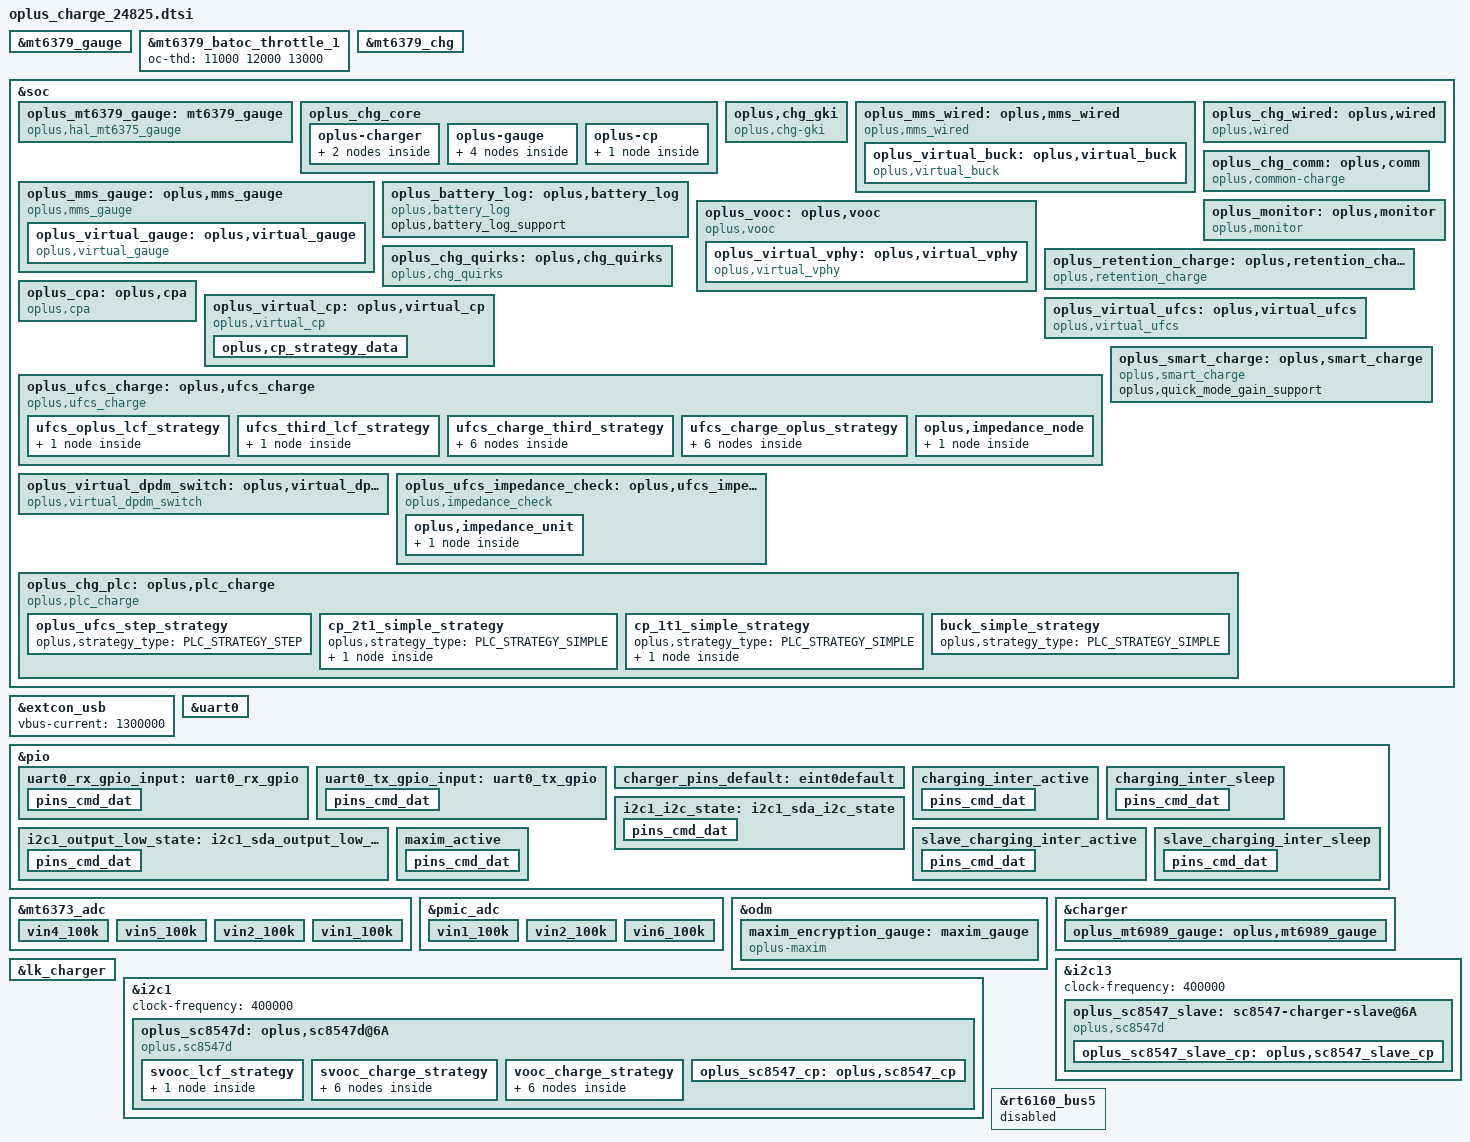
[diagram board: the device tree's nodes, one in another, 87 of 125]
// SPDX-License-Identifier: GPL-2.0-only
/*
* Copyright (C) 2024 Oplus. All rights reserved.
*/
#include <dt-bindings/iio/mt635x-auxadc.h>
#include <dt-bindings/iio/adc/mediatek,mt6379_auxadc.h>
#include <dt-bindings/pinctrl/mt6989-pinfunc.h>
#include <dt-bindings/pinctrl/mt65xx.h>
#include "oplus_chg.h"

/*
 *
 * CPU:MT6989V2 Subaru bcompare with MT6989V1 Nvwa, Platform Gauge Dtsi Config.
 *
 * UTXD0	-->GPIO203
 * URXD0	-->GPIO204
 *
 * I2C
 * MASTER_CHG	--> I2C5 MT6379 (GPIO99_SDA5, GPIO98_SCL5)
 * CP_MASTER	--> I2C1 SC8547D (GPIO101_SDA1, GPIO100_SCL1)
 * CP_SLAVE	--> I2C3 SC8547D (GPIO105_SDA3, GPIO104_SCL3)
 * Audio switch--> I2C6 Audio switch (GPIO226_SDA5, GPIO225_SCL5)
 *
 * IRQB
 * EINT_CHG_1 (cp1 irq)			--> GPIO83
 * EINT_CHG_2 (cp2 irq)			--> GPIO200
 * MT6375Z irq				--> GPIO175
 *
 * GPIO
 * VBUS_SHORT(防烧口)			--> MT6373 MOS_CON1
 * SEC_IC (加密电池GPIO for 80W)	--> GPIO190
 * 区分平台电量计和外置电量计GPIO	--> GPIO208 (低是石墨，高是硅负, 默认高电平)
 *
 *
 * ADC:
 * MT6363-GPIO1				--> VBAT_TEMP_ADC (电池仓温度检测NTC)(小板ntc温度)
 * MT6379 BATON				--> BATON_TH (电池保护板温度)
 * MT6363-GPIO6				--> USBCON_TEM_ADC_MCU (usb btb)
 *
 * MT6373 AUXADC_VIN4			--> USB_TEMP_ADC1 防烧口NTC1
 * MT6373 AUXADC_VIN5			--> USB_TEMP_ADC1 防烧口NTC2
 * MT6363 AUXADC_VIN1			--> CP_MOS_THERM 充电温度检测ntc   CP_TEM_ADC  靠近快充CP2和副电池BTB放置(3-6mm)
 * MT6363-GPIO2				--> BATCON_TEM_ADC_MCU (battery btb)
 *
 */

/* charge start */
&mt6379_gauge {
	status = "okay";
	charger = <&mt6379_chg>;
	FUELGAGUE_APPLY = <(1)>;
	IS_SUBBOARD_TEMP_SUPPORT = <(0)>;
	EXTERNAL_AUTHENTICATE =<(1)>;
	Enable_Is_Force_Full = <(1)>;

	active-table = <(5)>;
	r-fg-value = <(1)>;/* R_sense resistance. evb1 use 2; evb2 and later use 1 milliohm */
	com-r-fg-value = <(-1)>;/* R_sense compensate resistance. use COM_R_FG_VALUE */
	UNIT_MULTIPLE = <(1)>;
	RBAT_PULL_DOWN_R = <(24000)>;
	RBAT_PULL_UP_R = <(12000)>;
	RBAT_PULL_UP_VOLT = <(1840)>; /* Need to upadted  based on the PCB design.*/
	USE_MORE_PRECISE_NTC_TABLE = <(1)>;
	car-tune-value = <(99)>;      /* Current Calibration, need to upadted  based on the PCB design.*/
	DIM2_TABLE_DISTINGUISH = <(1)>;
	keep-100-percent-minsoc = <(9500)>;
	aging-factor-diff = <(1)>;
	keep-100-percent = <(2)>;

	/* compensate The resistance of PCB */
	com-fg-meter-resistance = <(-17)>;

	/* The resistance of PCB */
	fg-meter-resistance = <(-17)>;
	#include "bat_setting/mt6989_battery_prop_dim2_ext_24825.dtsi"
	#include "bat_setting/mt6989_battery_table_24825.dtsi"
};

&mt6379_batoc_throttle_1 {
	/* update the batoc-thd to avoid the issue of bat_oc interrup when the master BTB not connected */
	oc-thd = <11000 12000 13000>;
};

&mt6379_chg {
	chg-tmr = <15>;
	ircmp_v = <0>;
};

&soc {
	oplus_mt6379_gauge: mt6379_gauge {
		status = "okay";
		compatible = "oplus,hal_mt6375_gauge";

		oplus,ic_type = <OPLUS_CHG_IC_GAUGE>;
		oplus,ic_index = <0>;
		oplus,batt_num = <1>;
		oplus,mtk_gauge_power_sel_support;
		oplus,mtk_gauge_cali_track_support;
		oplus,mtk_gauge_power_sel_by_power_support;

		/* subaru graphite sub btb valid temperature range, which is provided by hardware engineer. */
		oplus,sub_btb_valid_temp = <(-350) 1000>;
	};
};

&extcon_usb {
	vbus-current = <1300000>;
};

&uart0 {
	pinctrl-names = "uart0_rx_gpio", "uart0_tx_gpio";
	pinctrl-0 = <&uart0_rx_gpio_input>;
	pinctrl-1 = <&uart0_tx_gpio_input>;
	status = "okay";

	txpin = <203>;
	rxpin = <204>;
};

&pio {
	uart0_rx_gpio_input: uart0_rx_gpio {
		pins_cmd_dat {
			pinmux = <PINMUX_GPIO204__FUNC_GPIO204>;
			input-enable;
			bias-disable;
		};
	};

	uart0_tx_gpio_input: uart0_tx_gpio {
		pins_cmd_dat {
			pinmux = <PINMUX_GPIO203__FUNC_GPIO203>;
			input-enable;
			bias-disable;
		};
	};
};

/* mt6373_adc is defined in mt6373.dtsi */
&mt6373_adc {
	vin4_100k {
		channel = <AUXADC_VIN4>;
		pures = <ADC_PURES_100K>;
	};
	vin5_100k {
		channel = <AUXADC_VIN5>;
		pures = <ADC_PURES_100K>;
	};
	vin2_100k {
		channel = <AUXADC_VIN2>;
		pures = <ADC_PURES_100K>;
	};
	vin1_100k {
		channel = <AUXADC_VIN1>;
		pures = <ADC_PURES_100K>;
	};
};

/* pmic_adc is defined in mt6363.dtsi */
&pmic_adc {
	vin1_100k {
		channel = <AUXADC_VIN1>;
		pures = <ADC_PURES_100K>;
	};
	vin2_100k {
		channel = <AUXADC_VIN2>;
		pures = <ADC_PURES_100K>;
	};
	vin6_100k {
		channel = <AUXADC_VIN6>;
		pures = <ADC_PURES_100K>;
	};
};

&pio {
	charger_pins_default: eint0default {
	};

	charging_inter_active: charging_inter_active {
		pins_cmd_dat {
			pinmux = <PINMUX_GPIO83__FUNC_GPIO83>;
			input-enable;
			bias-pull-up;
		};
	};

	charging_inter_sleep: charging_inter_sleep {
		pins_cmd_dat {
			pinmux = <PINMUX_GPIO83__FUNC_GPIO83>;
			input-enable;
			bias-pull-up;
		};
	};

	i2c1_i2c_state: i2c1_sda_i2c_state {
		pins_cmd_dat {
			pinmux = <PINMUX_GPIO100__FUNC_SCL1>,
				 <PINMUX_GPIO101__FUNC_SDA1>;
			bias-disable;
		};
	};

	i2c1_output_low_state: i2c1_sda_output_low_state {
		pins_cmd_dat {
			pinmux = <PINMUX_GPIO100__FUNC_GPIO100>,
				 <PINMUX_GPIO101__FUNC_GPIO101>;
			output-low;
		};
	};

	slave_charging_inter_active: slave_charging_inter_active {
		pins_cmd_dat {
			pinmux = <PINMUX_GPIO200__FUNC_GPIO200>;
			input-enable;
			bias-pull-up;
		};
	};

	slave_charging_inter_sleep: slave_charging_inter_sleep {
		pins_cmd_dat {
			pinmux = <PINMUX_GPIO200__FUNC_GPIO200>;
			input-enable;
			bias-pull-up;
		};
	};
};

&soc {
	oplus_chg_core {
		oplus,chg_framework_v2;
		oplus,battery_type_by_cmdline;
		oplus,smart_charging_screenoff;
		oplus,chg_spec_version = <OPLUS_CHG_SPEC_VER_V3P7>;

		oplus-charger {
			mtk_6989_groups: oplus,mtk_6989_groups {
				functions = <
					OPLUS_IC_FUNC_INIT
					OPLUS_IC_FUNC_EXIT
					OPLUS_IC_FUNC_REG_DUMP
					OPLUS_IC_FUNC_SMT_TEST
					OPLUS_IC_FUNC_BUCK_INPUT_PRESENT
					OPLUS_IC_FUNC_BUCK_INPUT_SUSPEND
					OPLUS_IC_FUNC_BUCK_INPUT_IS_SUSPEND
					OPLUS_IC_FUNC_BUCK_OUTPUT_SUSPEND
					OPLUS_IC_FUNC_BUCK_OUTPUT_IS_SUSPEND
					OPLUS_IC_FUNC_BUCK_SET_ICL
					OPLUS_IC_FUNC_BUCK_GET_ICL
					OPLUS_IC_FUNC_BUCK_SET_FCC
					OPLUS_IC_FUNC_BUCK_SET_FV
					OPLUS_IC_FUNC_BUCK_SET_ITERM
					OPLUS_IC_FUNC_BUCK_GET_INPUT_CURR
					OPLUS_IC_FUNC_BUCK_GET_INPUT_VOL
					OPLUS_IC_FUNC_OTG_BOOST_ENABLE
					OPLUS_IC_FUNC_BUCK_GET_CC_ORIENTATION
					OPLUS_IC_FUNC_BUCK_GET_CHARGER_TYPE
					OPLUS_IC_FUNC_BUCK_RERUN_BC12
					OPLUS_IC_FUNC_BUCK_QC_DETECT_ENABLE
					OPLUS_IC_FUNC_BUCK_SET_QC_CONFIG
					OPLUS_IC_FUNC_BUCK_SET_PD_CONFIG
					OPLUS_IC_FUNC_GET_SHUTDOWN_SOC
					OPLUS_IC_FUNC_BACKUP_SOC
					OPLUS_IC_FUNC_GET_TYPEC_MODE
					OPLUS_IC_FUNC_SET_TYPEC_MODE
					OPLUS_IC_FUNC_GET_TYPEC_ROLE
					OPLUS_IC_FUNC_GET_OTG_ENABLE
					OPLUS_IC_FUNC_BUCK_GET_HW_DETECT
					OPLUS_IC_FUNC_SET_USB_DISCHG_ENABLE
					OPLUS_IC_FUNC_GET_USB_DISCHG_STATUS
					OPLUS_IC_FUNC_IS_OPLUS_SVID
					OPLUS_IC_FUNC_BUCK_GET_USB_BTB_TEMP
					OPLUS_IC_FUNC_BUCK_GET_BATT_BTB_TEMP
					OPLUS_IC_FUNC_BUCK_SHIPMODE_ENABLE
					OPLUS_IC_FUNC_BUCK_SET_AICL_POINT
					OPLUS_IC_FUNC_SET_OTG_BOOST_CURR_LIMIT
					OPLUS_IC_FUNC_SET_OTG_BOOST_VOL
					OPLUS_IC_FUNC_BUCK_GET_FV
					OPLUS_IC_FUNC_BUCK_GET_TYPEC_STATE
					OPLUS_IC_FUNC_BUCK_GET_USB_AICL_ENHANCE
				>;
				virqs = <
					OPLUS_IC_VIRQ_ERR
					OPLUS_IC_VIRQ_CC_DETECT
					OPLUS_IC_VIRQ_PLUGIN
					OPLUS_IC_VIRQ_CC_CHANGED
					OPLUS_IC_VIRQ_CHG_TYPE_CHANGE
					OPLUS_IC_VIRQ_OTG_ENABLE
					OPLUS_IC_VIRQ_SVID
					OPLUS_IC_VIRQ_TYPEC_STATE
					OPLUS_IC_VIRQ_PD_COMPLETED
				>;
			};

			byb_tps6128xd_groups: oplus,byb-tps6128xd-groups {
				functions = <
					OPLUS_IC_FUNC_INIT
					OPLUS_IC_FUNC_EXIT
					OPLUS_IC_FUNC_REG_DUMP
				>;
				virqs = <
					OPLUS_IC_VIRQ_ERR
				>;
			};
		};

		oplus-gauge {
			mt6379_gauge_groups: oplus,mt6379_gauge_groups {
				functions = <
					OPLUS_IC_FUNC_INIT
					OPLUS_IC_FUNC_EXIT
					OPLUS_IC_FUNC_REG_DUMP
					OPLUS_IC_FUNC_SMT_TEST
					OPLUS_IC_FUNC_GAUGE_GET_BATT_VOL
					OPLUS_IC_FUNC_GAUGE_GET_BATT_MAX
					OPLUS_IC_FUNC_GAUGE_GET_BATT_MIN
					OPLUS_IC_FUNC_GAUGE_GET_BATT_CURR
					OPLUS_IC_FUNC_GAUGE_GET_BATT_TEMP
					OPLUS_IC_FUNC_GAUGE_GET_BATT_SOC
					OPLUS_IC_FUNC_GAUGE_GET_BATT_FCC
					OPLUS_IC_FUNC_GAUGE_GET_BATT_CC
					OPLUS_IC_FUNC_GAUGE_GET_BATT_RM
					OPLUS_IC_FUNC_GAUGE_GET_BATT_SOH
					OPLUS_IC_FUNC_GAUGE_GET_BATT_HMAC
					OPLUS_IC_FUNC_GAUGE_SET_BATT_FULL
					OPLUS_IC_FUNC_GAUGE_UPDATE_DOD0
					OPLUS_IC_FUNC_GAUGE_UPDATE_SOC_SMOOTH
					OPLUS_IC_FUNC_GAUGE_GET_CB_STATUS
					OPLUS_IC_FUNC_GAUGE_GET_BATT_NUM
					OPLUS_IC_FUNC_GAUGE_GET_DEVICE_TYPE
					OPLUS_IC_FUNC_GAUGE_GET_DEVICE_TYPE_FOR_VOOC
					OPLUS_IC_FUNC_GAUGE_GET_BATT_FCC
					OPLUS_IC_FUNC_GAUGE_GET_BATT_FC
					OPLUS_IC_FUNC_GAUGE_GET_BATT_QM
					OPLUS_IC_FUNC_GAUGE_GET_BATT_PD
					OPLUS_IC_FUNC_GAUGE_GET_BATT_RCU
					OPLUS_IC_FUNC_GAUGE_GET_BATT_RCF
					OPLUS_IC_FUNC_GAUGE_GET_BATT_FCU
					OPLUS_IC_FUNC_GAUGE_GET_BATT_FCF
					OPLUS_IC_FUNC_GAUGE_GET_BATT_SOU
					OPLUS_IC_FUNC_GAUGE_GET_BATT_DO0
					OPLUS_IC_FUNC_GAUGE_GET_BATT_DOE
					OPLUS_IC_FUNC_GAUGE_GET_BATT_TRM
					OPLUS_IC_FUNC_GAUGE_GET_BATT_PC
					OPLUS_IC_FUNC_GAUGE_GET_BATT_QS
					OPLUS_IC_FUNC_GAUGE_IS_SUSPEND
					OPLUS_IC_FUNC_GAUGE_GET_BCC_PARMS
					OPLUS_IC_FUNC_GAUGE_FASTCHG_UPDATE_BCC_PARMS
					OPLUS_IC_FUNC_GAUGE_GET_PREV_BCC_PARMS
					OPLUS_IC_FUNC_GAUGE_SET_BCC_PARMS
					OPLUS_IC_FUNC_GAUGE_SET_PROTECT_CHECK
					OPLUS_IC_FUNC_GAUGE_GET_AFI_UPDATE_DONE
					OPLUS_IC_FUNC_GAUGE_CHECK_RESET
					OPLUS_IC_FUNC_GAUGE_GET_DEVICE_TYPE_FOR_BCC
					OPLUS_IC_FUNC_GAUGE_GET_DOD0
					OPLUS_IC_FUNC_GAUGE_GET_DOD0_PASSED_Q
					OPLUS_IC_FUNC_GAUGE_GET_QMAX
					OPLUS_IC_FUNC_GAUGE_GET_QMAX_PASSED_Q
					OPLUS_IC_FUNC_GAUGE_SET_BATTERY_CURVE
					OPLUS_IC_FUNC_GAUGE_GET_GAUGE_CAR_C
					OPLUS_IC_FUNC_GAUGE_GET_SUB_BTB_CONNECT_STATE
					OPLUS_IC_FUNC_GAUGE_GET_DEC_FG_TYPE
					OPLUS_IC_FUNC_GAUGE_GET_DEC_CV_SOH
					OPLUS_IC_FUNC_GAUGE_SET_VCT
					OPLUS_IC_FUNC_GAUGE_GET_VCT
				>;
				virqs = <
					OPLUS_IC_VIRQ_ERR
					OPLUS_IC_VIRQ_OFFLINE
					OPLUS_IC_VIRQ_RESUME
				>;
			};

			mt6989_gauge_groups: oplus,mt6989_gauge_groups {
				functions = <
					OPLUS_IC_FUNC_INIT
					OPLUS_IC_FUNC_EXIT
					OPLUS_IC_FUNC_GAUGE_GET_SUBBOARD_TEMP
				>;
				virqs = <
					OPLUS_IC_VIRQ_ERR
				>;
			};

			maxim_encryption_gauge_groups: oplus,maxim_encryption_gauge_groups {
				functions = <
					OPLUS_IC_FUNC_INIT
					OPLUS_IC_FUNC_EXIT
					OPLUS_IC_FUNC_GAUGE_GET_BATT_AUTH
				>;
				virqs = <
					OPLUS_IC_VIRQ_ERR
				>;
			};

			bq27541_groups: oplus,bq27541_groups {
				functions = <
					OPLUS_IC_FUNC_INIT
					OPLUS_IC_FUNC_EXIT
					OPLUS_IC_FUNC_REG_DUMP
					OPLUS_IC_FUNC_SMT_TEST
					OPLUS_IC_FUNC_GAUGE_GET_BATT_VOL
					OPLUS_IC_FUNC_GAUGE_GET_BATT_MAX
					OPLUS_IC_FUNC_GAUGE_GET_BATT_MIN
					OPLUS_IC_FUNC_GAUGE_GET_BATT_CURR
					OPLUS_IC_FUNC_GAUGE_GET_BATT_TEMP
					OPLUS_IC_FUNC_GAUGE_GET_BATT_SOC
					OPLUS_IC_FUNC_GAUGE_GET_BATT_FCC
					OPLUS_IC_FUNC_GAUGE_GET_BATT_CC
					OPLUS_IC_FUNC_GAUGE_GET_BATT_RM
					OPLUS_IC_FUNC_GAUGE_GET_BATT_SOH
					OPLUS_IC_FUNC_GAUGE_GET_BATT_AUTH
					OPLUS_IC_FUNC_GAUGE_GET_BATT_HMAC
					OPLUS_IC_FUNC_GAUGE_SET_BATT_FULL
					OPLUS_IC_FUNC_GAUGE_UPDATE_DOD0
					OPLUS_IC_FUNC_GAUGE_UPDATE_SOC_SMOOTH
					OPLUS_IC_FUNC_GAUGE_GET_CB_STATUS
					OPLUS_IC_FUNC_GAUGE_GET_BATT_NUM
					OPLUS_IC_FUNC_GAUGE_GET_DEVICE_TYPE
					OPLUS_IC_FUNC_GAUGE_GET_DEVICE_TYPE_FOR_VOOC
					OPLUS_IC_FUNC_GAUGE_GET_BATT_FCC
					OPLUS_IC_FUNC_GAUGE_GET_BATT_FC
					OPLUS_IC_FUNC_GAUGE_GET_BATT_QM
					OPLUS_IC_FUNC_GAUGE_GET_BATT_PD
					OPLUS_IC_FUNC_GAUGE_GET_BATT_RCU
					OPLUS_IC_FUNC_GAUGE_GET_BATT_RCF
					OPLUS_IC_FUNC_GAUGE_GET_BATT_FCU
					OPLUS_IC_FUNC_GAUGE_GET_BATT_FCF
					OPLUS_IC_FUNC_GAUGE_GET_BATT_SOU
					OPLUS_IC_FUNC_GAUGE_GET_BATT_DO0
					OPLUS_IC_FUNC_GAUGE_GET_BATT_DOE
					OPLUS_IC_FUNC_GAUGE_GET_BATT_TRM
					OPLUS_IC_FUNC_GAUGE_GET_BATT_PC
					OPLUS_IC_FUNC_GAUGE_GET_BATT_QS
					OPLUS_IC_FUNC_GAUGE_IS_SUSPEND
					OPLUS_IC_FUNC_GAUGE_GET_BCC_PARMS
					OPLUS_IC_FUNC_GAUGE_FASTCHG_UPDATE_BCC_PARMS
					OPLUS_IC_FUNC_GAUGE_GET_PREV_BCC_PARMS
					OPLUS_IC_FUNC_GAUGE_SET_BCC_PARMS
					OPLUS_IC_FUNC_GAUGE_SET_PROTECT_CHECK
					OPLUS_IC_FUNC_GAUGE_GET_AFI_UPDATE_DONE
					OPLUS_IC_FUNC_GAUGE_CHECK_RESET
					OPLUS_IC_FUNC_GAUGE_SET_RESET
					OPLUS_IC_FUNC_GAUGE_GET_DEVICE_TYPE_FOR_BCC
					OPLUS_IC_FUNC_GAUGE_GET_DOD0
					OPLUS_IC_FUNC_GAUGE_GET_DOD0_PASSED_Q
					OPLUS_IC_FUNC_GAUGE_GET_QMAX
					OPLUS_IC_FUNC_GAUGE_GET_QMAX_PASSED_Q
					OPLUS_IC_FUNC_GAUGE_GET_REG_INFO
					OPLUS_IC_FUNC_GAUGE_GET_CALIB_TIME
					OPLUS_IC_FUNC_GAUGE_GET_DEEP_DISCHG_COUNT
					OPLUS_IC_FUNC_GAUGE_SET_DEEP_DISCHG_COUNT
					OPLUS_IC_FUNC_GAUGE_GET_DEEP_TERM_VOLT
					OPLUS_IC_FUNC_GAUGE_SET_DEEP_TERM_VOLT
					OPLUS_IC_FUNC_GAUGE_SET_SILI_SPARE_POWER
					OPLUS_IC_FUNC_GAUGE_GET_SILI_SIMULATE_TERM_VOLT
					OPLUS_IC_FUNC_GAUGE_GET_SILI_IC_ALG_TERM_VOLT
					OPLUS_IC_FUNC_GAUGE_SET_SILI_IC_ALG_CFG
					OPLUS_IC_FUNC_GAUGE_GET_SILI_IC_ALG_DSG_ENABLE
					OPLUS_IC_FUNC_GAUGE_SET_SILI_IC_ALG_TERM_VOLT
					OPLUS_IC_FUNC_GAUGE_GET_SILI_ALG_APPLICATION_INFO
					OPLUS_IC_FUNC_GAUGE_GET_SILI_LIFETIME_STATUS
					OPLUS_IC_FUNC_GAUGE_GET_SILI_LIFETIME_INFO
					OPLUS_IC_FUNC_GAUGE_SET_CALIB_TIME
					OPLUS_IC_FUNC_GAUGE_SET_LAST_CC
					OPLUS_IC_FUNC_GAUGE_GET_LAST_CC
				>;
				virqs = <
					OPLUS_IC_VIRQ_ERR
					OPLUS_IC_VIRQ_OFFLINE
					OPLUS_IC_VIRQ_RESUME
				>;
			};
		};

		oplus-cp {
			sc8547_cp_groups: oplus,cp_groups {
				functions = <
					OPLUS_IC_FUNC_INIT
					OPLUS_IC_FUNC_EXIT
					OPLUS_IC_FUNC_REG_DUMP
					OPLUS_IC_FUNC_SMT_TEST
					OPLUS_IC_FUNC_CP_ENABLE
					OPLUS_IC_FUNC_CP_HW_INTI
					OPLUS_IC_FUNC_CP_SET_WORK_START
					OPLUS_IC_FUNC_CP_CHECK_WORK_MODE_SUPPORT
					OPLUS_IC_FUNC_CP_SET_WORK_MODE
					OPLUS_IC_FUNC_CP_GET_WORK_MODE
					OPLUS_IC_FUNC_CP_GET_VIN
					OPLUS_IC_FUNC_CP_GET_IIN
					OPLUS_IC_FUNC_CP_SET_IIN
					OPLUS_IC_FUNC_CP_GET_VOUT
					OPLUS_IC_FUNC_CP_GET_IOUT
					OPLUS_IC_FUNC_CP_GET_VAC
					OPLUS_IC_FUNC_CP_GET_WORK_STATUS
					OPLUS_IC_FUNC_CP_SET_ADC_ENABLE
					OPLUS_IC_FUNC_CP_WATCHDOG_ENABLE
					OPLUS_IC_FUNC_CP_SET_UCP_DISABLE
					OPLUS_IC_FUNC_CP_GET_IIN_MAX
					OPLUS_IC_FUNC_CP_WATCHDOG_RESET
				>;
				virqs = <
					OPLUS_IC_VIRQ_ERR
					OPLUS_IC_VIRQ_ONLINE
					OPLUS_IC_VIRQ_OFFLINE
				>;
			};
		};
	};
};


&pio {
	maxim_active: maxim_active {
		pins_cmd_dat {
			pinmux = <PINMUX_GPIO190__FUNC_GPIO190>;
				//slew-rate = <1>;
				drive-strength = <6>;
				bias-pull-up;
			};
		};
};

&odm {
	maxim_encryption_gauge: maxim_gauge {
		status = "okay";
		compatible = "oplus-maxim";
		pinctrl-names = "maxim_active";
		pinctrl-0 = <&maxim_active>;
		support_encryption_in_lk;
		data-gpio = <&pio 190 0x00>;

		gpio-addr-set-out = <0x10005004>;
		gpio-addr-set-in = <0x10005008>;
		gpio-addr-level_high = <0x10005104>;
		gpio-addr-level_low = <0x10005108>;
		gpio-addr-data-in = <0x10005200>;
		gpio-addr-offset = <0xbe>;

		/* TODO: need to update when the battery material code updated */
		oplus,batt_info = /bits/ 8 <0x36 0x31 0x31 0x33 0x30 0x33 0x30 0x30 0x30 0x31 0x33 0x31
					    0x36 0x31 0x31 0x33 0x30 0x33 0x30 0x30 0x30 0x32 0x32 0x38>;

		oplus,ic_type = <OPLUS_CHG_IC_GAUGE>;
		oplus,ic_index = <2>;
	};
};

&soc {
	oplus,chg_gki {
		compatible = "oplus,chg-gki";
	};
};

&charger {
	io-channels = <&pmic_adc (ADC_PURES_100K_MASK | AUXADC_VIN2)>,
			<&mt6373_adc AUXADC_VIN1>,
			<&pmic_adc (ADC_PURES_100K_MASK | AUXADC_VIN1)>,
			<&pmic_adc (ADC_PURES_100K_MASK | AUXADC_VIN2)>,
			<&pmic_adc (ADC_PURES_100K_MASK | AUXADC_VIN6)>,
			<&mt6373_adc AUXADC_VIN1>;
	io-channel-names = "master_cp_temp","slave_cp_temp", "auxadc1-ntc_sub_bat_tem",
			   "auxadc5_batt_btb_temp", "auxadc6_usb_btb_temp", "sub_bat_btb_temp";

	pinctrl-names = "default";
	pinctrl-0 = <&charger_pins_default>;
	oplus,support_ntc_01c_precision;
	oplus,support_subboard_ntc;
	max_charger_voltage = <15000000>;

	/* ntc_resistance:100k internal_pull_up:100k voltage:1.84v */
	oplus,ntc_temp_volt_1840mv;

	/* usbtemp dischg use pmic regulator to set vbus down */
	oplus,support_usbtemp_dischg_reg_configurable;
	oplus,usbtemp_dischg_reg_addr = <0x989>;
	oplus,usbtemp_dischg_reg_mask = <0x7>;
	oplus,usbtemp_dischg_enable = <0x2>;
	oplus,usbtemp_dischg_disable = <0x0>;
	oplus,ic_type = <OPLUS_CHG_IC_BUCK>;
	oplus,ic_index = <0>;

	oplus,usb_aicl_enhance;

	oplus_mt6989_gauge: oplus,mt6989_gauge {
		oplus,ic_type = <OPLUS_CHG_IC_GAUGE>;
		oplus,ic_index = <1>;
	};
};

&lk_charger {
	is_support_mt6379;
	en_vol_ctrl_vibrate = <3200>;
	support_tuv_authentication;
	high-temp-scheme;
	charger_no_wiress;
	support_battery_type = <8>;
	support_maxim_battery_authentication;
	data-gpio = <190>;

	/* TODO: need to update when the battery material code updated */
	oplus,batt_info = /bits/ 8 <0x36 0x31 0x31 0x33 0x30 0x33 0x30 0x30 0x30 0x31 0x33 0x31
				    0x36 0x31 0x31 0x33 0x30 0x33 0x30 0x30 0x30 0x32 0x32 0x38>;

	oplus,batt_resource_info = /bits/ 8 <1 0>;
	sub_board_temp_support;
	over_high_temp_thr = <60>;
	sub_board_adc_channel = <18>; /* AUXADC_VIN1 */
	sub_board_adc_pull_up_voltage = <1840>;

	support_sdp_screenoff;
	sdp_screenon_voltage = <3250>;
	support_quickboot_charge;

	/* mt6989 start */
	led-brightness = <102>;

	/* mt6989, such as max_charger_voltage to max-charger-voltage */
	max-charger-voltage = <15000000>;
	boot-battery-voltage = <3350000>;
	usb-charger-current = <500000>;
	ac-charger-current = <2050000>;
	ac-charger-input-current = <1500000>;
	non-std-ac-charger-current = <750000>;
	charging-host-charger-current = <1500000>;
	ta-ac-charger-current = <1500000>;
	pd-charger-current = <500000>;

	/* support to read the vbat by the 6379 gauge. */
	mt6379_gauge_support;

	/* support to get the gauge type by the board gpio. */
	gauge_type_by_gpio = <208>;

	/* 1: silicon, 0: graphite. */
	gauge_silicon_gpio_value = <1>;
	/* mt6989 end */
};

&soc {
	oplus_mms_wired: oplus,mms_wired {
		compatible = "oplus,mms_wired";
		oplus,buck_ic = <&oplus_virtual_buck>;
		oplus,voocphy_ic = <&oplus_virtual_vphy>;

		oplus,adc_info_name = "100k_1840mv";
		oplus_spec,usbtemp_batttemp_gap = <12>;
		high-temp-scheme;

		/* support for V2.0 usbtemp protect. */
		oplus,support_usbtemp_protect_v2;
		oplus_spec,usbtemp_batt_temp_low = <50>;
		oplus_spec,usbtemp_batt_temp_high = <50>;
		oplus_spec,usbtemp_batt_temp_over_hot = <60>;
		oplus_spec,usbtemp_ntc_temp_low = <57>;
		oplus_spec,usbtemp_ntc_temp_high = <69>;
		oplus_spec,usbtemp_temp_gap_low_with_batt_temp = <7>;
		oplus_spec,usbtemp_temp_gap_with_batt_temp_in_over_hot = <15>;
		oplus_spec,usbtemp_temp_gap_high_with_batt_temp = <12>;
		oplus_spec,usbtemp_temp_gap_low_without_batt_temp = <12>;
		oplus_spec,usbtemp_temp_gap_high_without_batt_temp = <24>;
		oplus_spec,usbtemp_rise_fast_temp_low = <3>;
		oplus_spec,usbtemp_rise_fast_temp_high = <3>;
		oplus_spec,usbtemp_rise_fast_temp_count_low = <30>;
		oplus_spec,usbtemp_rise_fast_temp_count_high = <20>;
		oplus_spec,usbtemp_cool_down_ntc_low = <54>;
		oplus_spec,usbtemp_cool_down_ntc_high = <65>;
		oplus_spec,usbtemp_cool_down_gap_low = <12>;
		oplus_spec,usbtemp_cool_down_gap_high = <20>;
		oplus_spec,usbtemp_cool_down_recover_ntc_low = <48>;
		oplus_spec,usbtemp_cool_down_recover_ntc_high = <60>;
		oplus_spec,usbtemp_cool_down_recover_gap_low = <6>;
		oplus_spec,usbtemp_cool_down_recover_gap_high = <15>;
		oplus_spec,usbtemp_otg_cc_boot_current_limit = <1300000>;

		oplus_virtual_buck: oplus,virtual_buck {
			compatible = "oplus,virtual_buck";
			oplus,buck_ic = <&charger>;
			oplus,buck_ic_index = <0>;
			oplus,buck_ic_current_ratio = <100>;
			oplus,buck_ic_connect = <OPLUS_CHG_IC_CONNECT_PARALLEL>;
			oplus,main_charger = <0>;

			oplus,buck_ic_func_group = <&mtk_6989_groups>;

			oplus,ic_type = <OPLUS_CHG_IC_VIRTUAL_BUCK>;
			oplus,ic_index = <0>;

			io-channels = <&mt6373_adc AUXADC_VIN4>, <&mt6373_adc AUXADC_VIN5>;
			io-channel-names = "usb_temp_adc_l", "usb_temp_adc_r";

			oplus,uart_tx-gpio = <&pio 203 0x00>;
			oplus,uart_rx-gpio = <&pio 204 0x00>;
		};
	};

	oplus_mms_gauge: oplus,mms_gauge {
		compatible = "oplus,mms_gauge";
		oplus,gauge_ic = <&oplus_virtual_gauge>;
		oplus,voocphy_ic = <&oplus_virtual_vphy>;
		oplus,topic-update-interval = <10000>;
		oplus,support_subboard_ntc;
		oplus,sub_btb_curr_limit = <3000>; /* Online current limiting, provided by hardware engineer */

		oplus_virtual_gauge: oplus,virtual_gauge {
			compatible = "oplus,virtual_gauge";
			oplus,gauge_ic =  <&oplus_mt6379_gauge &oplus_mt6989_gauge &maxim_encryption_gauge>;
			plus,gauge_ic_index = <0 1 2>;
			oplus,gauge_ic_func_group = <&mt6379_gauge_groups &mt6989_gauge_groups &maxim_encryption_gauge_groups>;
			oplus,batt_capacity_mah = <7100>;
			oplus,ic_type = <OPLUS_CHG_IC_VIRTUAL_GAUGE>;
			oplus,ic_index = <0>;
		};
	};
};

&soc {
	oplus_battery_log: oplus,battery_log {
		compatible = "oplus,battery_log";
		oplus,battery_log_support;
	};

	oplus_chg_wired: oplus,wired {
		compatible = "oplus,wired";

		oplus,vooc-support;
		oplus_spec,vbatt_pdqc_to_5v_thr = <4500>;
		oplus_spec,vbatt_pdqc_to_9v_thr = <4500>;
		oplus_spec,pd-iclmax-ma = <2000>;
		oplus_spec,qc-iclmax-ma = <2000>;
		oplus_spec,non-standard-ibatmax-ma = <500>;
		oplus_spec,input-power-mw = <
			2500		/* OPLUS_WIRED_CHG_MODE_UNKNOWN */
			2500		/* OPLUS_WIRED_CHG_MODE_SDP */
			7500		/* OPLUS_WIRED_CHG_MODE_CDP */
			10000		/* OPLUS_WIRED_CHG_MODE_DCP */
			18000		/* OPLUS_WIRED_CHG_MODE_VOOC */
			18000		/* OPLUS_WIRED_CHG_MODE_QC */
			18000		/* OPLUS_WIRED_CHG_MODE_PD */
		>;
		oplus_spec,led_on-fccmax-ma = <0 1732 4400 4400 4400 4400 4400 1000 0>;
		oplus_spec,fccmax-ma-lv = <
			0 1363 2200 2200 2200 2200 2200 2200 0	/* OPLUS_WIRED_CHG_MODE_UNKNOWN */
			0 600  600  600  600  600  600  600  0	/* OPLUS_WIRED_CHG_MODE_SDP */
			0 1600 1600 1600 1600 1600 1600 1600 0	/* OPLUS_WIRED_CHG_MODE_CDP */
			0 1732 2200 2200 2200 2200 2200 2200 0	/* OPLUS_WIRED_CHG_MODE_DCP */
			0 1732 4400 4400 4400 4400 4400 3811 0	/* OPLUS_WIRED_CHG_MODE_VOOC */
			0 1732 4400 4400 4400 4400 4400 3811 0	/* OPLUS_WIRED_CHG_MODE_QC */
			0 1732 4400 4400 4400 4400 4400 3811 0	/* OPLUS_WIRED_CHG_MODE_PD */
		>;
		oplus_spec,fccmax-ma-hv = <
			0 1363 2200 2200 2200 2200 2200 1000 0	/* OPLUS_WIRED_CHG_MODE_UNKNOWN */
			0 600  600  600  600  600  600  500 0	/* OPLUS_WIRED_CHG_MODE_SDP */
			0 1600 1600 1600 1600 1600 1600 1000 0	/* OPLUS_WIRED_CHG_MODE_CDP */
			0 1732 2200 2200 2200 2200 2200 1000 0	/* OPLUS_WIRED_CHG_MODE_DCP */
			0 1732 4400 4400 4400 4400 4400 1000 0	/* OPLUS_WIRED_CHG_MODE_VOOC */
			0 1732 4400 4400 4400 4400 4400 1000 0	/* OPLUS_WIRED_CHG_MODE_QC */
			0 1732 4400 4400 4400 4400 4400 1000 0	/* OPLUS_WIRED_CHG_MODE_PD */
		>;
		oplus_spec,cool_down_sale_pdqc_vol_mv = <5000>;
		oplus_spec,cool_down_sale_pdqc_curr_ma = <1200>;
		oplus_spec,cool_down_pdqc_vol_mv = <5000 5000 5000 9000 9000>;
		oplus_spec,cool_down_pdqc_curr_ma = <1200 1500 2000 1500 2000>;
		oplus_spec,cool_down_vooc_curr_ma = <1200 1500 2000 2500 3000 3000>;
		oplus_spec,cool_down_normal_curr_ma = <1200 1500 2000>;

		oplus_spec,vbus_ov_thr_mv = <11000 11000>;
		oplus_spec,vbus_uv_thr_mv = <4300 4300>;

		/* Temperature control for power off charging. */
		/* first data is strategy used temp type */
		oplus,pd_strategy_name = "cgcl";
		oplus,pd_strategy_data = <OPLUS_STRATEGY_USE_SHELL_TEMP
					    0   420 2000 1 0
					    410 430 1500 2 0
					    420 440 1200 2 1>;

		oplus,qc_strategy_name = "cgcl";
		oplus,qc_strategy_data = <OPLUS_STRATEGY_USE_SHELL_TEMP
					    0   420 2000 1 0
					    410 430 1500 2 0
					    420 440 1200 2 1>;
	};

	oplus_chg_comm: oplus,comm {
		compatible = "oplus,common-charge";
		oplus_spec,dec_step = <20>;
		oplus_spec,dec-vol-cc-full-thr = <0 400 600 800 1000 1200>;
		oplus_spec,dec-vol-fv-full-mv = <0 20 20 40 40 40>;
		oplus_spec,batt-them-thr = <(-100) 0 50 120 160 350 450 530>;
		oplus_spec,iterm-ma = <365>; /* 7100*0.05+10 */
		oplus_spec,removed_bat_decidegc = <390>; /*-39 degree*/
		oplus_spec,fv-mv = <4490 4490 4490 4490 4490 4490 4470 4130 4130>;
		oplus_spec,sw-fv-mv = <4440 4440 4440 4440 4440 4440 4420 4080 4080>;
		oplus_spec,hw-fv-inc-mv = <0 18 18 18 18 18 18 18 0>;
		oplus_spec,sw-over-fv-mv = <4500 4500 4500 4500 4500 4500 4480 4140 4140>;
		oplus_spec,sw-over-fv-dec-mv = <8>;
		oplus_spec,non-standard-sw-fv-mv = <3930>;
		oplus_spec,non-standard-fv-mv = <3980>;
		oplus_spec,non-standard-hw-fv-inc-mv = <18>;
		oplus_spec,non-standard-sw-over-fv-mv = <3990>;
		oplus_spec,non-standard-vbatdet-mv = <3680>;
		oplus_spec,wired-vbatdet-mv = <0 4190 4290 4390 4390 4390 4370 4030 0>;
		oplus_spec,fcc-gear-thr-mv = <4180>;
		oplus_spec,fcc-gear-shake-mv = <700 700 400 250 200 150 150 100 100>;
		oplus_spec,vbatt-ov-thr-mv = <4600>;

		oplus_spec,full_pre_ffc_judge;
		oplus_spec,full-pre-ffc-mv = <4500>;
		oplus_spec,ffc-temp-thr = <120 210 350 440>;
		oplus_spec,wired-ffc-step-max = <2>;
		oplus_spec,wired-ffc-fv-mv = <4630 4630>;

		oplus_spec,wired-ffc-fv-cutoff-mv = <4565 4550 4520
						     4565 4535 4495>;
		oplus_spec,wired-ffc-fcc-ma = <1750 1500 1500
					       1650 1000 1000>;
		oplus_spec,wired-ffc-fcc-cutoff-ma = <1550 1300 1300
						      1550 900 900>;
		oplus_spec,vbat_uv_thr_mv = <3300>;
		oplus_spec,vbat_charging_uv_thr_mv = <3200>;

		oplus_spec,tbatt_power_off_cali_temp = <0>;
		oplus_spec,poweroff_high_batt_temp = <720>;
		oplus_spec,poweroff_emergency_batt_temp = <770>;
		oplus,vooc_show_ui_soc_decimal;
		oplus,ui_soc_decimal_speedmin = <20>;
		oplus,gauge_stuck_jump_support;
		oplus,gauge_stuck_threshold = <15>;
		oplus,gauge_stuck_time = <50>;

		oplus_spec,batt_full_time = <300>;
	};

	oplus_monitor: oplus,monitor {
		compatible = "oplus,monitor";
		oplus,topic-update-interval = <60000>;

		track,fast_chg_break_t_thd = <1400>;
		track,general_chg_break_t_thd = <300>;
		track,voocphy_type = <TRACK_AP_DUAL_CP_VOOCPHY>;
		track,wired_max_power = <80000>;
		track,wired_fast_chg_scheme = <2>;
	};

	oplus_vooc: oplus,vooc {
		compatible = "oplus,vooc";
		oplus,vooc_ic = <&oplus_virtual_vphy>;

		oplus_spec,vooc_soc_range = <50 75 85>;

		oplus,vooc_data_width = <7>;
		oplus,vooc_curr_max = <CP_CURR_LIMIT_7BIT_15_0A>; /* 80W: 11V 7.3A(IBUS *2) */
		oplus,vooc_power_max_w = <80>;
		oplus,vooc_project = <7>;
		oplus,vooc_curr_table_type = <VOOC_CP_CURR_TABLE>;
		oplus,voocphy_support = <3>; /* AP_DUAL_CP_VOOCPHY */
		oplus,support_fake_vooc_check;
		oplus,subboard_ntc_abnormal_current = <4000>;
		oplus,cp_cooldown_limit_percent_75 = <CP_CURR_LIMIT_7BIT_8_0A>;
		oplus,cp_cooldown_limit_percent_85 = <CP_CURR_LIMIT_7BIT_4_0A>;

		oplus,abnormal_adapter_current = <CP_CURR_LIMIT_7BIT_15_0A CP_CURR_LIMIT_7BIT_15_0A
						CP_CURR_LIMIT_7BIT_10_0A CP_CURR_LIMIT_7BIT_10_0A
						CP_CURR_LIMIT_7BIT_8_0A CP_CURR_LIMIT_7BIT_8_0A
						CP_CURR_LIMIT_7BIT_6_0A CP_CURR_LIMIT_7BIT_6_0A
						CP_CURR_LIMIT_7BIT_4_0A CP_CURR_LIMIT_7BIT_4_0A>;

		oplus,abnormal_over_80w_adapter_current = <CP_CURR_LIMIT_7BIT_15_0A CP_CURR_LIMIT_7BIT_15_0A
						CP_CURR_LIMIT_7BIT_14_0A CP_CURR_LIMIT_7BIT_14_0A
						CP_CURR_LIMIT_7BIT_12_0A CP_CURR_LIMIT_7BIT_12_0A
						CP_CURR_LIMIT_7BIT_10_0A CP_CURR_LIMIT_7BIT_10_0A
						CP_CURR_LIMIT_7BIT_8_0A CP_CURR_LIMIT_7BIT_8_0A
						CP_CURR_LIMIT_7BIT_6_0A CP_CURR_LIMIT_7BIT_6_0A
						CP_CURR_LIMIT_7BIT_4_0A CP_CURR_LIMIT_7BIT_4_0A>;

		/* Temperature control for power off charging */
		/* first data is strategy used temp type */
		oplus,general_strategy_name = "cgcl";
		oplus,general_strategy_data = < OPLUS_STRATEGY_USE_SHELL_TEMP
						0   385 CP_CURR_LIMIT_7BIT_15_0A 1 0
						375 405 CP_CURR_LIMIT_7BIT_10_0A 2 0
						395 420 CP_CURR_LIMIT_7BIT_8_0A 3 1
						410 430 CP_CURR_LIMIT_7BIT_7_0A 4 2
						425 440 CP_CURR_LIMIT_7BIT_4_0A 4 3 >;

		oplus,bypass_strategy_name = "cgcl";
		oplus,bypass_strategy_data = <OPLUS_STRATEGY_USE_SHELL_TEMP
						0   350 CP_CURR_LIMIT_7BIT_6_0A 1 0
						340 380 CP_CURR_LIMIT_7BIT_5_0A 2 0
						370 440 CP_CURR_LIMIT_7BIT_4_0A 2 1>;

		oplus,plc_strategy-data = <&buck_simple_strategy &cp_2t1_simple_strategy &cp_1t1_simple_strategy>;
		oplus,plc_strategy-names = "default", "svooc", "vooc";

		oplus_virtual_vphy: oplus,virtual_vphy {
			compatible = "oplus,virtual_vphy";
			oplus,vphy_ic = <&oplus_sc8547d>;

			oplus,ic_type = <OPLUS_CHG_IC_VIRTUAL_VPHY>;
			oplus,ic_index = <0>;
			oplus,dpdm_switch_ic = <&oplus_virtual_dpdm_switch>;
		};
	};

	oplus_chg_quirks: oplus,chg_quirks {
		compatible = "oplus,chg_quirks";
	};
	oplus_retention_charge: oplus,retention_charge {
		compatible = "oplus,retention_charge";
		oplus,topic-update-interval = <5000>;
		oplus,support_retention_name = "oplus_retention_quirks";
	};

	oplus_cpa: oplus,cpa {
		compatible = "oplus,cpa";
		oplus,protocol_list = <CHG_PROTOCOL_UFCS 80
				       CHG_PROTOCOL_VOOC 80
				       CHG_PROTOCOL_PD 18
				       CHG_PROTOCOL_QC 18>;
		oplus,default_protocol_list = <CHG_PROTOCOL_UFCS
					       CHG_PROTOCOL_VOOC
					       CHG_PROTOCOL_PD>;

		oplus,protocol_wait_list = <CHG_PROTOCOL_UFCS 1000>;
	};

	oplus_virtual_cp: oplus,virtual_cp {
		compatible = "oplus,virtual_cp";

		oplus,ic_type = <OPLUS_CHG_IC_VIRTUAL_CP>;
		oplus,ic_index = <0>;

		oplus,cp_ic = <&oplus_sc8547_cp &oplus_sc8547_slave_cp>;
		oplus,input_curr_max_ma = <4000 4000>;

		oplus,cp_ic_connect = <OPLUS_CHG_IC_CONNECT_PARALLEL>;
		oplus,main_cp = <0>;

		oplus,reg_proc_node;

		oplus,cp_strategy = <CP_STRAT_OPEN_BY_CURR>;
		oplus,cp_strategy_data {
			oplus,cp_open_curr_thr_ma = <0 1900>;
			oplus,cp_close_curr_thr_ma = <0 1600>;
		};
	};

	oplus_virtual_ufcs: oplus,virtual_ufcs {
		compatible = "oplus,virtual_ufcs";

		oplus,ic_type = <OPLUS_CHG_IC_VIRTUAL_UFCS>;
		oplus,ic_index = <0>;
	};

	oplus_ufcs_charge: oplus,ufcs_charge {
		compatible = "oplus,ufcs_charge";
		oplus,ufcs_ic = <&oplus_virtual_ufcs>;
		oplus,cp_ic = <&oplus_virtual_cp>;
		oplus,dpdm_switch_ic = <&oplus_virtual_dpdm_switch>;

		oplus,impedance_unit = <&oplus_ufcs_impedance_unit>;
		oplus,ufcs_need_reset_adapter;

		oplus,target_vbus_mv = <11000>;
		oplus,curr_max_ma = <7300>;
		oplus,curr_table_type = <UFCS_CURR_CP_TABLE>;
		oplus,high_imp_compensation_setting_mv = <250>;
		oplus,upper_compensation_mv = <200>;
		oplus,lift_vbus_use_cpvout;
		oplus,subboard_ntc_abnormal_current = <4000>;

		oplus,ufcs_warm_allow_vol = <4000>;
		oplus,ufcs_warm_allow_soc = <50>;
		oplus,ufcs_strategy_normal_current = <7300>;
		oplus,ufcs_over_high_or_low_current = <7300>;
		oplus,ufcs_timeout_third = <17820>;
		oplus,ufcs_timeout_oplus = <17820>;
		oplus,ufcs_ibat_over_third = <9400>;
		oplus,ufcs_ibat_over_oplus = <16000>;
		oplus,ufcs_full_cool_sw_vbat = <4570>;
		oplus,ufcs_full_normal_sw_vbat = <4570>;
		oplus,ufcs_full_normal_hw_vbat = <4580>;
		oplus,ufcs_full_ffc_vbat = <4520>;
		oplus,ufcs_full_warm_vbat = <4130>;
		oplus,ufcs_full_cool_sw_vbat_third = <4500>;
		oplus,ufcs_full_normal_sw_vbat_third= <4510>;
		oplus,ufcs_full_normal_hw_vbat_third = <4520>;
		oplus,ufcs_current_change_timeout = <100>;
		oplus,ufcs_strategy_batt_high_temp = <405 420 430 395 410 425>;
		oplus,ufcs_strategy_high_current = <5000 4000 3000 5000 4000 3000>;
		oplus,ufcs_little_cool_high_temp = <210>;
		oplus,curve_strategy_name = "pps_ufcs_curve_v2";
		oplus_spec,ufcs_high_soc = <90>;
		oplus_spec,ufcs_high_soc_third = <85>;
		oplus,ufcs_charge_strategy_soc = <0 20 35 50 75 85 90>;
		oplus,ufcs_charge_strategy_temp = <0 50 120 160 350 440 510>;

		oplus,plc_strategy-data = <&oplus_ufcs_step_strategy &cp_2t1_simple_strategy>;
		oplus,plc_strategy-names = "default", "third";

		/* Temperature control for power off charging */
		oplus,temperature_strategy_name = "cgcl";
		oplus,temperature_strategy_data = <OPLUS_STRATEGY_USE_SHELL_TEMP
						0   385 7300 1 0
						375 405 5000 2 0
						395 420 4000 3 1
						410 430 3500 4 2
						420 440 2000 4 3>;

		ufcs_oplus_lcf_strategy {
			oplus,temp_type = <OPLUS_STRATEGY_USE_SHELL_TEMP>;
			oplus,temp_range = <0 50 120 160 210 380 440>;

			strategy_temp_range_curves {
				strategy_temp_range_t0 =	<800 4570 0
								 750 4560 0
								 700 4550 0
								 650 4540 0
								 600 4530 1>;
				strategy_temp_range_t1 =	<950 4570 0
								 900 4565 0
								 850 4550 0
								 750 4540 0
								 650 4530 1>;
				strategy_temp_range_t2 =	<1050 4570 0
								 1000 4565 0
								 900 4550 0
								 800 4540 0
								 650 4530 1>;
				strategy_temp_range_t3 =	<1600 4570 0
								 1550 4565 0
								 1450 4550 0
								 1350 4540 0
								 1200 4530 1>;
				strategy_temp_range_t4 =	<2150 4570 0
								 2100 4565 0
								 2000 4550 0
								 1900 4540 0
								 1750 4530 1>;
				strategy_temp_range_t5 =	<2900 4565 0
								 2450 4550 0
								 2000 4530 0
								 1500 4510 0
								 1000 4495 1>;
			};
		};

		ufcs_third_lcf_strategy {
			oplus,temp_type = <OPLUS_STRATEGY_USE_SHELL_TEMP>;
			oplus,temp_range = <0 50 120 160 210 380 440>;

			strategy_temp_range_curves {
				strategy_temp_range_t0 =	<800 4570 0
								 750 4560 0
								 700 4550 0
								 650 4540 0
								 600 4530 1>;
				strategy_temp_range_t1 =	<950 4570 0
								 900 4565 0
								 850 4550 0
								 750 4540 0
								 650 4530 1>;
				strategy_temp_range_t2 =	<1050 4570 0
								 1000 4565 0
								 900 4550 0
								 800 4540 0
								 650 4530 1>;
				strategy_temp_range_t3 =	<1600 4570 0
								 1550 4565 0
								 1450 4550 0
								 1350 4540 0
								 1200 4530 1>;
				strategy_temp_range_t4 =	<2150 4570 0
								 2100 4565 0
								 2000 4550 0
								 1900 4540 0
								 1750 4530 1>;
				strategy_temp_range_t5 =	<2900 4565 0
								 2450 4550 0
								 2000 4530 0
								 1500 4510 0
								 1000 4495 1>;
			};
		};

		ufcs_charge_third_strategy {
			oplus,temp_type = <OPLUS_STRATEGY_USE_SHELL_TEMP>;
			oplus,soc_range = <0 20 35 55 75 85 90>;
			oplus,temp_range = <0 50 120 160 210 350 440 510>;

			strategy_soc_range_min {
				strategy_temp_little_cold =	<11000 4150 3950 0 0
								11000 4150 3500 0 0
								11000 4150 3000 0 0
								11000 4480 2650 0 0
								11000 4480 2500 0 0
								11000 4480 2000 0 0
								11000 4480 1950 0 0
								11000 4480 1500 0 0
								11000 4490 1000 1 0>;
				strategy_temp_cool =		<11000 4150 4000 0 0
								11000 4480 3950 0 0
								11000 4480 3500 0 0
								11000 4480 3000 0 0
								11000 4480 2650 0 0
								11000 4480 2500 0 0
								11000 4480 2000 0 0
								11000 4480 1500 0 0
								11000 4490 1000 1 0>;
				strategy_temp_little_cool =	<11000 4480 4000 0 0
								11000 4480 3500 0 0
								11000 4480 3000 0 0
								11000 4480 2500 0 0
								11000 4480 2000 0 0
								11000 4480 1500 0 0
								11000 4490 1000 1 0>;
				strategy_temp_little_cool_high =	<11000 4480 4000 0 0
								11000 4480 3500 0 0
								11000 4480 3000 0 0
								11000 4480 2500 0 0
								11000 4480 2000 0 0
								11000 4480 1500 0 0
								11000 4490 1000 1 0>;
				strategy_temp_normal_low =	<11000 4480 4000 0 0
								11000 4480 3500 0 0
								11000 4480 3000 0 0
								11000 4480 2500 0 0
								11000 4480 2000 0 0
								11000 4480 1500 0 0
								11000 4490 1000 1 0>;
				strategy_temp_normal_high =	<11000 4460 4000 0 0
								11000 4460 3500 0 0
								11000 4460 3000 0 0
								11000 4460 2500 0 0
								11000 4460 2000 0 0
								11000 4460 1500 0 0
								11000 4470 1000 1 0>;
				strategy_temp_warm =		<11000 4120 1900 0 0
								11000 4120 1500 0 0
								11000 4130 1000 1 0>;
			};
			strategy_soc_range_low {
				strategy_temp_little_cold =	<11000 4150 3950 0 0
								11000 4150 3500 0 0
								11000 4150 3000 0 0
								11000 4480 2650 0 0
								11000 4480 2500 0 0
								11000 4480 2000 0 0
								11000 4480 1950 0 0
								11000 4480 1500 0 0
								11000 4490 1000 1 0>;
				strategy_temp_cool =		<11000 4150 4000 0 0
								11000 4480 3950 0 0
								11000 4480 3500 0 0
								11000 4480 3000 0 0
								11000 4480 2650 0 0
								11000 4480 2500 0 0
								11000 4480 2000 0 0
								11000 4480 1500 0 0
								11000 4490 1000 1 0>;
				strategy_temp_little_cool =	<11000 4480 4000 0 0
								11000 4480 3500 0 0
								11000 4480 3000 0 0
								11000 4480 2500 0 0
								11000 4480 2000 0 0
								11000 4480 1500 0 0
								11000 4490 1000 1 0>;
				strategy_temp_little_cool_high =	<11000 4480 4000 0 0
								11000 4480 3500 0 0
								11000 4480 3000 0 0
								11000 4480 2500 0 0
								11000 4480 2000 0 0
								11000 4480 1500 0 0
								11000 4490 1000 1 0>;
				strategy_temp_normal_low =	<11000 4480 4000 0 0
								11000 4480 3500 0 0
								11000 4480 3000 0 0
								11000 4480 2500 0 0
								11000 4480 2000 0 0
								11000 4480 1500 0 0
								11000 4490 1000 1 0>;
				strategy_temp_normal_high =	<11000 4460 4000 0 0
								11000 4460 3500 0 0
								11000 4460 3000 0 0
								11000 4460 2500 0 0
								11000 4460 2000 0 0
								11000 4460 1500 0 0
								11000 4470 1000 1 0>;
				strategy_temp_warm =		<11000 4120 1900 0 0
								11000 4120 1500 0 0
								11000 4130 1000 1 0>;
			};
			strategy_soc_range_mid_low {
				strategy_temp_little_cold =	<11000 4480 2000 0 0
								11000 4480 1950 0 0
								11000 4480 1500 0 0
								11000 4490 1000 1 0>;
				strategy_temp_cool =		<11000 4480 2500 0 0
								11000 4480 2000 0 0
								11000 4480 1500 0 0
								11000 4490 1000 1 0>;
				strategy_temp_little_cool =	<11000 4480 3000 0 0
								11000 4480 2500 0 0
								11000 4480 2000 0 0
								11000 4480 1500 0 0
								11000 4490 1000 1 0>;
				strategy_temp_little_cool_high =	<11000 4480 3000 0 0
								11000 4480 2500 0 0
								11000 4480 2000 0 0
								11000 4480 1500 0 0
								11000 4490 1000 1 0>;
				strategy_temp_normal_low =	<11000 4480 4000 0 0
								11000 4480 3500 0 0
								11000 4480 3000 0 0
								11000 4480 2500 0 0
								11000 4480 2000 0 0
								11000 4480 1500 0 0
								11000 4490 1000 1 0>;
				strategy_temp_normal_high =	<11000 4460 4000 0 0
								11000 4460 3500 0 0
								11000 4460 3000 0 0
								11000 4460 2500 0 0
								11000 4460 2000 0 0
								11000 4460 1500 0 0
								11000 4470 1000 1 0>;
				strategy_temp_warm =		<11000 4120 1900 0 0
								11000 4120 1500 0 0
								11000 4130 1000 1 0>;
			};
			strategy_soc_range_mid {
				strategy_temp_little_cold =	<11000 4480 1500 0 0
								11000 4490 1000 1 0>;
				strategy_temp_cool =		<11000 4480 1500 0 0
								11000 4490 1000 1 0>;
				strategy_temp_little_cool =	<11000 4480 2000 0 0
								11000 4480 1500 0 0
								11000 4490 1000 1 0>;
				strategy_temp_little_cool_high =	<11000 4480 2000 0 0
								11000 4480 1500 0 0
								11000 4490 1000 1 0>;
				strategy_temp_normal_low =	<11000 4480 2000 0 0
								11000 4480 1500 0 0
								11000 4490 1000 1 0>;
				strategy_temp_normal_high =	<11000 4460 2500 0 0
								11000 4460 2000 0 0
								11000 4460 1500 0 0
								11000 4470 1000 1 0>;
				strategy_temp_warm =		<11000 4130 1100 1 0>;
			};
			strategy_soc_range_mid_high {
				strategy_temp_little_cold =	<11000 4490 1000 1 0>;
				strategy_temp_cool =		<11000 4490 1000 1 0>;
				strategy_temp_little_cool =	<11000 4490 1000 1 0>;
				strategy_temp_little_cool_high =	<11000 4490 1000 1 0>;
				strategy_temp_normal_low =	<11000 4480 1500 0 0
								11000 4490 1000 1 0>;
				strategy_temp_normal_high =	<11000 4460 1500 0 0
								11000 4470 1000 1 0>;
				strategy_temp_warm =		<11000 4130 1100 1 0>;
			};
			strategy_soc_range_high {
				strategy_temp_little_cold =	<11000 4490 1100 1 0>;
				strategy_temp_cool =		<11000 4490 1100 1 0>;
				strategy_temp_little_cool =	<11000 4490 1100 1 0>;
				strategy_temp_little_cool_high =	<11000 4490 1100 1 0>;
				strategy_temp_normal_low =	<11000 4490 1100 1 0>;
				strategy_temp_normal_high =	<11000 4470 1100 1 0>;
				strategy_temp_warm =		<11000 4130 1100 1 0>;
			};
		};

		ufcs_charge_oplus_strategy {
			oplus,temp_type = <OPLUS_STRATEGY_USE_SHELL_TEMP>;
			oplus,soc_range = <0 20 35 55 75 85 90>;
			oplus,temp_range = <0 50 120 160 210 350 440 510>;

			strategy_soc_range_min {
				strategy_temp_little_cold =	<11000 4150 3950 0 0
								11000 4150 3500 0 0
								11000 4150 3000 0 0
								11000 4510 2650 0 0
								11000 4510 2500 0 0
								11000 4510 2000 0 0
								11000 4560 1950 0 0
								11000 4560 1500 0 0
								11000 4570 1000 1 0>;
				strategy_temp_cool =		<11000 4150 4950 0 0
								11000 4150 4500 0 0
								11000 4150 4000 0 0
								11000 4510 3950 0 0
								11000 4510 3500 0 0
								11000 4510 3000 0 0
								11000 4560 2650 0 0
								11000 4560 2500 0 0
								11000 4560 2000 0 0
								11000 4560 1500 0 0
								11000 4570 1000 1 0>;
				strategy_temp_little_cool =	<11000 4150 7300 0 60
								11000 4150 6100 0 180
								11000 4510 5950 0 240
								11000 4510 5000 0 180
								11000 4560 4650 0 240
								11000 4560 4000 0 300
								11000 4560 3500 0 0
								11000 4560 3000 0 0
								11000 4560 2500 0 0
								11000 4560 2000 0 0
								11000 4560 1500 0 0
								11000 4570 1000 1 0>;
				strategy_temp_little_cool_high =	<11000 4280 7300 0 30
								11000 4510 6300 0 30
								11000 4510 5000 0 240
								11000 4560 4650 0 300
								11000 4560 4000 0 600
								11000 4560 3500 0 0
								11000 4560 3000 0 0
								11000 4560 2500 0 0
								11000 4560 2000 0 0
								11000 4560 1500 0 0
								11000 4570 1000 1 0>;
				strategy_temp_normal_low =	<11000 4280 7300 0 30
								11000 4510 6300 0 30
								11000 4510 5000 0 240
								11000 4560 4650 0 300
								11000 4560 4000 0 600
								11000 4560 3500 0 0
								11000 4560 3000 0 0
								11000 4560 2500 0 0
								11000 4560 2000 0 0
								11000 4560 1500 0 0
								11000 4570 1100 1 0>;
				strategy_temp_normal_high =	<11000 4280 7300 0 30
								11000 4510 6300 0 30
								11000 4510 5000 0 240
								11000 4560 4650 0 300
								11000 4560 4000 0 900
								11000 4560 3500 0 0
								11000 4560 3000 0 0
								11000 4560 2500 0 0
								11000 4560 2000 0 0
								11000 4570 1500 0 0
								11000 4530 1000 1 0>;
				strategy_temp_warm =		<11000 4120 1900 0 0
								11000 4120 1500 0 0
								11000 4130 1000 1 0>;
			};
			strategy_soc_range_low {
				strategy_temp_little_cold =	<11000 4150 3950 0 0
								11000 4150 3500 0 0
								11000 4150 3000 0 0
								11000 4510 2650 0 0
								11000 4510 2500 0 0
								11000 4510 2000 0 0
								11000 4560 1950 0 0
								11000 4560 1500 0 0
								11000 4570 1000 1 0>;
				strategy_temp_cool =		<11000 4150 4950 0 0
								11000 4150 4500 0 0
								11000 4150 4000 0 0
								11000 4510 3950 0 0
								11000 4510 3500 0 0
								11000 4510 3000 0 0
								11000 4560 2650 0 0
								11000 4560 2500 0 0
								11000 4560 2000 0 0
								11000 4560 1500 0 0
								11000 4570 1000 1 0>;
				strategy_temp_little_cool =	<11000 4150 7300 0 60
								11000 4150 6100 0 180
								11000 4510 5950 0 240
								11000 4510 5000 0 180
								11000 4560 4650 0 240
								11000 4560 4000 0 300
								11000 4560 3500 0 0
								11000 4560 3000 0 0
								11000 4560 2500 0 0
								11000 4560 2000 0 0
								11000 4560 1500 0 0
								11000 4570 1000 1 0>;
				strategy_temp_little_cool_high =	<11000 4280 7300 0 30
								11000 4510 6300 0 30
								11000 4510 5000 0 240
								11000 4560 4650 0 300
								11000 4560 4000 0 600
								11000 4560 3500 0 0
								11000 4560 3000 0 0
								11000 4560 2500 0 0
								11000 4560 2000 0 0
								11000 4560 1500 0 0
								11000 4570 1000 1 0>;
				strategy_temp_normal_low =	<11000 4280 7300 0 30
								11000 4510 6300 0 30
								11000 4510 5000 0 240
								11000 4560 4650 0 300
								11000 4560 4000 0 600
								11000 4560 3500 0 0
								11000 4560 3000 0 0
								11000 4560 2500 0 0
								11000 4560 2000 0 0
								11000 4560 1500 0 0
								11000 4570 1100 1 0>;
				strategy_temp_normal_high =	<11000 4280 7300 0 30
								11000 4510 6300 0 30
								11000 4510 5000 0 240
								11000 4560 4650 0 300
								11000 4560 4000 0 600
								11000 4560 3500 0 0
								11000 4560 3000 0 0
								11000 4560 2500 0 0
								11000 4560 2000 0 0
								11000 4570 1500 0 0
								11000 4530 1000 1 0>;
				strategy_temp_warm =		<11000 4120 1900 0 0
								11000 4120 1500 0 0
								11000 4130 1000 1 0>;
			};
			strategy_soc_range_mid_low {
						strategy_temp_little_cold =	<11000 4510 2000 0 0
								11000 4560 1950 0 0
								11000 4560 1500 0 0
								11000 4570 1000 1 0>;
				strategy_temp_cool =		<11000 4560 2500 0 0
								11000 4560 2000 0 0
								11000 4560 1500 0 0
								11000 4570 1000 1 0>;
				strategy_temp_little_cool =	<11000 4560 4000 0 300
								11000 4560 3500 0 0
								11000 4560 3000 0 0
								11000 4560 2500 0 0
								11000 4560 2000 0 0
								11000 4560 1500 0 0
								11000 4570 1000 1 0>;
				strategy_temp_little_cool_high =	<11000 4560 4000 0 0
								11000 4560 3500 0 0
								11000 4560 3000 0 0
								11000 4560 2500 0 0
								11000 4560 2000 0 0
								11000 4560 1500 0 0
								11000 4570 1000 1 0>;
				strategy_temp_normal_low =	<11000 4280 7300 0 30
								11000 4510 6300 0 30
								11000 4510 5000 0 240
								11000 4560 4650 0 300
								11000 4560 4000 0 600
								11000 4560 3500 0 0
								11000 4560 3000 0 0
								11000 4560 2500 0 0
								11000 4560 2000 0 0
								11000 4560 1500 0 0
								11000 4570 1100 1 0>;
				strategy_temp_normal_high =	<11000 4280 7300 0 30
								11000 4510 6300 0 30
								11000 4510 5000 0 240
								11000 4560 4650 0 300
								11000 4560 4000 0 600
								11000 4560 3500 0 0
								11000 4560 3000 0 0
								11000 4560 2500 0 0
								11000 4560 2000 0 0
								11000 4570 1500 0 0
								11000 4530 1000 1 0>;
				strategy_temp_warm =		<11000 4120 1900 0 0
								11000 4120 1500 0 0
								11000 4130 1000 1 0>;
			};
			strategy_soc_range_mid {
				strategy_temp_little_cold =	<11000 4560 1500 0 0
								11000 4570 1000 1 0>;
				strategy_temp_cool =		<11000 4560 1500 0 0
								11000 4570 1000 1 0>;
				strategy_temp_little_cool =	<11000 4560 2000 0 0
								11000 4560 1500 0 0
								11000 4570 1000 1 0>;
				strategy_temp_little_cool_high =	<11000 4560 2000 0 0
								11000 4560 1500 0 0
								11000 4570 1000 1 0>;
				strategy_temp_normal_low =	<11000 4560 2500 0 0
								11000 4560 2000 0 0
								11000 4560 1500 0 0
								11000 4570 1100 1 0>;
				strategy_temp_normal_high =	<11000 4560 3000 0 0
								11000 4560 2500 0 0
								11000 4560 2000 0 0
								11000 4570 1500 0 0
								11000 4530 1000 1 0>;
				strategy_temp_warm =		<11000 4130 1100 1 0>;
			};
			strategy_soc_range_mid_high {
				strategy_temp_little_cold =	<11000 4570 1000 1 0>;
				strategy_temp_cool =		<11000 4570 1000 1 0>;
				strategy_temp_little_cool =	<11000 4560 1500 0 0
								11000 4570 1000 1 0>;
				strategy_temp_little_cool_high =	<11000 4560 1500 0 0
								11000 4570 1000 1 0>;
				strategy_temp_normal_low =	<11000 4560 1500 0 0
								11000 4570 1100 1 0>;
				strategy_temp_normal_high =	<11000 4560 2000 0 0
								11000 4570 1500 0 0
								11000 4530 1000 1 0>;
				strategy_temp_warm =		<11000 4130 1100 1 0>;
			};
			strategy_soc_range_high {
				strategy_temp_little_cold =	<11000 4570 1000 1 0>;
				strategy_temp_cool =		<11000 4570 1000 1 0>;
				strategy_temp_little_cool =	<11000 4570 1000 1 0>;
				strategy_temp_little_cool_high =	<11000 4570 1000 1 0>;
				strategy_temp_normal_low =	<11000 4570 1100 1 0>;
				strategy_temp_normal_high =	<11000 4570 1500 0 0
								11000 4530 1000 1 0>;
				strategy_temp_warm =		<11000 4130 1100 1 0>;
			};
		};

		oplus,impedance_node {
			ufcs_input_impedance: ufcs_input_impedance {
				node_name = "ufcs_input";
				default_impedance_mohm = <0>;
				default_curr_ma = <7300>;
				current_drop_table = <
					125 10000
					130 8000
					190 5000
					250 4000
					340 3000
					380 2000
					480 0
				>;
			};
		};
	};

	oplus_virtual_dpdm_switch: oplus,virtual_dpdm_switch {
		compatible = "oplus,virtual_dpdm_switch";
		oplus,ic_type = <OPLUS_CHG_IC_MISC>;
		oplus,ic_index = <0>;

		oplus,use_audio_switch;
	};

	oplus_smart_charge: oplus,smart_charge {
		compatible = "oplus,smart_charge";
		oplus,quick_mode_gain_support;
	};
};

&soc {
	oplus_ufcs_impedance_check: oplus,ufcs_impedance_check {
		compatible = "oplus,impedance_check";

		oplus,impedance_unit {
			oplus_ufcs_impedance_unit: oplus,ufcs_impedance_unit {
				uint_name = "ufcs";
				default_curr_ma = <7300>;
				impedance_node = <&ufcs_input_impedance>;
			};
		};
	};
};

&i2c1 {
	status = "ok";
	clock-frequency = <400000>;

	oplus_sc8547d: oplus,sc8547d@6A {
		status = "okay";
		compatible = "oplus,sc8547d";
		reg = <0x6A>;
		oplus,use_vooc_phy;
		oplus,use_ufcs_phy;
		oplus,always_otg_en;

		oplus_spec,irq_gpio = <&pio 83 0x00>;
		interrupt-parent = <&pio>;
		interrupts = <83 0>;

		pinctrl-names = "charging_inter_active", "charging_inter_sleep", "i2c-state", "output-low-state";
		pinctrl-0 = <&charging_inter_active>;
		pinctrl-1 = <&charging_inter_sleep>;
		pinctrl-2 = <&i2c1_i2c_state>;
		pinctrl-3 = <&i2c1_output_low_state>;

		oplus,ic_type = <OPLUS_CHG_IC_VPHY>;
		oplus,ic_index = <0>;
		oplus,vooc-version = <VOOC_VERSION_5_0>;

		ocp_reg = <0xe>; /* IBUS_OCP */
		ovp_reg = <0x36>;/* vbat ovp 4.85v */
		vbus_ovp_reg = /bits/ 8 <0x5A>;  /* vbus ovp: 10.5v */
		oplus_spec,voocphy_dual_cp_support;
		oplus_spec,slave_cp_enable_thr = <1400>;        //2000-100mA
		oplus_spec,slave_cp_disable_thr_high = <1100>;  //1500+100mA
		oplus_spec,voocphy_current_default = <73>;
		oplus_spec,ap_control_allow;

		oplus_spec,svooc_cool_down_current_limit = <146 20 20 24 30 34 40 44 50 54 60 64 70 74>;
		oplus_spec,vooc_cool_down_current_limit = <73 20 20 24 30 34 40 44 50 54 60 64 70 74>;

		oplus_spec,vooc_multistep_initial_batt_temp = <1000>;
		oplus_spec,vooc_little_cool_temp = <160>;
		oplus_spec,vooc_little_cool_high_temp = <200>;
		oplus_spec,vooc_cool_temp = <120>;
		oplus_spec,vooc_little_cold_temp = <50>;
		oplus_spec,vooc_normal_low_temp = <350>;
		oplus_spec,vooc_strategy_normal_current = <146>;
		oplus_spec,vooc_normal_to_little_cool_current = <100>;
		oplus_spec,vooc_over_high_temp = <510>;
		oplus_spec,vooc_low_temp = <0>;
		oplus_spec,vooc_high_temp = <500>;
		oplus_spec,vooc_low_soc = <0>;
		oplus_spec,vooc_high_soc = <95>;
		oplus_spec,vooc_normal_high_temp = <440>;
		oplus_spec,vooc_warm_vol_thr = <4000>;
		oplus_spec,vooc_warm_soc_thr = <50>;

		oplus_spec,vooc_strategy1_batt_high_temp0 = <385>;
		oplus_spec,vooc_strategy1_batt_high_temp1 = <395>;
		oplus_spec,vooc_strategy1_batt_high_temp2 = <420>;
		oplus_spec,vooc_strategy1_batt_low_temp2 = <410>;
		oplus_spec,vooc_strategy1_batt_low_temp1 = <385>;
		oplus_spec,vooc_strategy1_batt_low_temp0 = <375>;

		oplus_spec,vooc_strategy1_high_current0 = <80>;
		oplus_spec,vooc_strategy1_high_current1 = <61>;
		oplus_spec,vooc_strategy1_high_current2 = <40>;
		oplus_spec,vooc_strategy1_low_current2 = <40>;
		oplus_spec,vooc_strategy1_low_current1 = <61>;
		oplus_spec,vooc_strategy1_low_current0 = <80>;

		oplus_spec,fastchg_timeout_time_init = <178200>;
		oplus_spec,voocphy_ibat_over_current = <16000>;
		oplus_spec,voocphy_svooc_cp_max_ibus = <5000>;
		oplus_spec,voocphy_vooc_cp_max_ibus = <5000>;
		oplus_spec,voocphy_cp_max_ibus = <5000>;

		oplus_spec,voocphy_freq_mincore = <1800000>;
		oplus_spec,voocphy_freq_midcore = <1918000>;
		oplus_spec,voocphy_freq_maxcore = <1918000>;
		oplus_spec,voocphy_current_change_timeout = <100>;
		oplus_spec,copycat_vooc_support;
		oplus_spec,copycat_vooc_accuracy_value = <105>;

		oplus_spec,vooc_little_cold_full_voltage = <4570>;
		oplus_spec,vooc_cool_full_voltage = <4570>;
		oplus_spec,vooc_little_cool_full_voltage = <4570>;
		oplus_spec,vooc_little_cool_high_full_voltage = <4570>;
		oplus_spec,vooc_warm_full_voltage = <4130>;
		oplus_spec,vooc_1time_full_voltage = <4580>;
		oplus_spec,vooc_ntime_full_voltage = <4570>;
		oplus_spec,soc_range = <0 20 35 55 75 85 90>;

		svooc_batt_sys_curve = <0 1 0 1 0 0 0	// 4000mA
					1 1 1 1 0 0 0	// 4604mV
					0 0 1 1 0 1 0	// 2600mA
					1 1 1 1 0 0 0	// 4604mV
					0 0 0 1 0 1 1	// 1100mA
					1 1 1 1 0 0 0>;	// 4604mV

		vooc_batt_sys_curve =  <0 1 0 1 0 0 0	// 4000mA
					1 1 1 1 0 0 0	// 4604mV
					0 0 1 1 0 1 0	// 2600mA
					1 1 1 1 0 0 0	// 4604mV
					0 0 0 1 0 1 1	// 1100mA
					1 1 1 1 0 0 0>;	// 4604mV

		svooc_lcf_strategy {
			oplus,temp_type = <OPLUS_STRATEGY_USE_SHELL_TEMP>;
			oplus,temp_range = <0 50 120 160 210 380 440>;

			strategy_temp_range_curves {
				strategy_temp_range_t0 =	<800 4570 0
								 750 4560 0
								 700 4550 0
								 650 4540 0
								 600 4530 1>;
				strategy_temp_range_t1 =	<950 4570 0
								 900 4565 0
								 850 4550 0
								 750 4540 0
								 650 4530 1>;
				strategy_temp_range_t2 =	<1050 4570 0
								 1000 4565 0
								 900 4550 0
								 800 4540 0
								 650 4530 1>;
				strategy_temp_range_t3 =	<1600 4570 0
								 1550 4565 0
								 1450 4550 0
								 1350 4540 0
								 1200 4530 1>;
				strategy_temp_range_t4 =	<2150 4570 0
								 2100 4565 0
								 2000 4550 0
								 1900 4540 0
								 1750 4530 1>;
				strategy_temp_range_t5 =	<2900 4565 0
								 2450 4550 0
								 2000 4530 0
								 1500 4510 0
								 1000 4495 1>;
			};
		};

		svooc_charge_strategy {
			strategy_soc_0_to_50 { /* 0 ~ 20 */
				strategy_temp_little_cold =	<4150 39 0 0 0
								4150 35 0 0 0
								4150 30 0 0 0
								4510 26 0 0 0
								4510 25 0 0 0
								4510 20 0 0 0
								4560 19 0 0 0
								4560 15 0 0 0
								4570 10 1 0 0>;
				strategy_temp_cool =		<4150 49 0 0 0
								4150 45 0 0 0
								4150 40 0 0 0
								4510 39 0 0 0
								4510 35 0 0 0
								4510 30 0 0 0
								4560 26 0 0 0
								4560 25 0 0 0
								4560 20 0 0 0
								4560 15 0 0 0
								4570 10 1 0 0>;
				strategy_temp_little_cool =	<4150 73 0 120 0
								4150 61 0 360 0
								4510 59 0 480 0
								4510 50 0 360 0
								4560 46 0 480 0
								4560 40 0 600 0
								4560 35 0 0 0
								4560 30 0 0 0
								4560 25 0 0 0
								4560 20 0 0 0
								4560 15 0 0 0
								4570 10 1 0 0>;
				strategy_temp_little_cool_high = <4280 73 0 60 0
								4510 63 0 60 0
								4510 50 0 480 0
								4560 46 0 600 0
								4560 40 0 1200 0
								4560 35 0 0 0
								4560 30 0 0 0
								4560 25 0 0 0
								4560 20 0 0 0
								4560 15 0 0 0
								4570 10 1 0 0>;
				strategy_temp_normal_low =	<4280 73 0 60 0
								4510 63 0 60 0
								4510 50 0 480 0
								4560 46 0 600 0
								4560 40 0 1200 0
								4560 35 0 0 0
								4560 30 0 0 0
								4560 25 0 0 0
								4560 20 0 0 0
								4560 15 0 0 0
								4570 11 1 0 0>;
				strategy_temp_normal_high =	<4280 73 0 60 0
								4510 63 0 60 0
								4510 50 0 480 0
								4560 46 0 600 0
								4560 40 0 1200 0
								4560 35 0 0 0
								4560 30 0 0 0
								4560 25 0 0 0
								4560 20 0 0 0
								4570 15 0 0 0
								4530 10 1 0 0>;
				strategy_temp_warm =		<4120 19 0 0 0
								4120 15 0 0 0
								4130 10 1 0 0>;
			};

			strategy_soc_0_to_50_mid { /* 21 ~ 35 */
				strategy_temp_little_cold =	<4150 39 0 0 0
								4150 35 0 0 0
								4150 30 0 0 0
								4510 26 0 0 0
								4510 25 0 0 0
								4510 20 0 0 0
								4560 19 0 0 0
								4560 15 0 0 0
								4570 10 1 0 0>;
				strategy_temp_cool =		<4150 49 0 0 0
								4150 45 0 0 0
								4150 40 0 0 0
								4510 39 0 0 0
								4510 35 0 0 0
								4510 30 0 0 0
								4560 26 0 0 0
								4560 25 0 0 0
								4560 20 0 0 0
								4560 15 0 0 0
								4570 10 1 0 0>;
				strategy_temp_little_cool =	<4150 73 0 120 0
								4150 61 0 360 0
								4510 59 0 480 0
								4510 50 0 360 0
								4560 46 0 480 0
								4560 40 0 600 0
								4560 35 0 0 0
								4560 30 0 0 0
								4560 25 0 0 0
								4560 20 0 0 0
								4560 15 0 0 0
								4570 10 1 0 0>;
				strategy_temp_little_cool_high = <4280 73 0 60 0
								4510 63 0 60 0
								4510 50 0 480 0
								4560 46 0 600 0
								4560 40 0 1200 0
								4560 35 0 0 0
								4560 30 0 0 0
								4560 25 0 0 0
								4560 20 0 0 0
								4560 15 0 0 0
								4570 10 1 0 0>;
				strategy_temp_normal_low =	<4280 73 0 60 0
								4510 63 0 60 0
								4510 50 0 480 0
								4560 46 0 600 0
								4560 40 0 1200 0
								4560 35 0 0 0
								4560 30 0 0 0
								4560 25 0 0 0
								4560 20 0 0 0
								4560 15 0 0 0
								4570 11 1 0 0>;
				strategy_temp_normal_high =	<4280 73 0 60 0
								4510 63 0 60 0
								4510 50 0 480 0
								4560 46 0 600 0
								4560 40 0 1200 0
								4560 35 0 0 0
								4560 30 0 0 0
								4560 25 0 0 0
								4560 20 0 0 0
								4570 15 0 0 0
								4530 10 1 0 0>;
				strategy_temp_warm =		<4120 19 0 0 0
								4120 15 0 0 0
								4130 10 1 0 0>;
			};

			strategy_soc_0_to_50_high { /* 36 ~ 55 */
				strategy_temp_little_cold =	<4510 20 0 0 0
								4560 19 0 0 0
								4560 15 0 0 0
								4570 10 1 0 0>;
				strategy_temp_cool =		<4560 25 0 0 0
								4560 20 0 0 0
								4560 15 0 0 0
								4570 10 1 0 0>;
				strategy_temp_little_cool =	<4560 40 0 0 0
								4560 35 0 0 0
								4560 30 0 0 0
								4560 25 0 0 0
								4560 20 0 0 0
								4560 15 0 0 0
								4570 10 1 0 0>;
				strategy_temp_little_cool_high = <4560 40 0 0 0
								4560 35 0 0 0
								4560 30 0 0 0
								4560 25 0 0 0
								4560 20 0 0 0
								4560 15 0 0 0
								4570 10 1 0 0>;
				strategy_temp_normal_low =	<4280 73 0 60 0
								4510 63 0 60 0
								4510 50 0 480 0
								4560 46 0 600 0
								4560 40 0 1200 0
								4560 35 0 0 0
								4560 30 0 0 0
								4560 25 0 0 0
								4560 20 0 0 0
								4560 15 0 0 0
								4570 11 1 0 0>;
				strategy_temp_normal_high =	<4280 73 0 60 0
								4510 63 0 60 0
								4510 50 0 480 0
								4560 46 0 600 0
								4560 40 0 1200 0
								4560 35 0 0 0
								4560 30 0 0 0
								4560 25 0 0 0
								4560 20 0 0 0
								4570 15 0 0 0
								4530 10 1 0 0>;
				strategy_temp_warm =		<4120 19 0 0 0
								4120 15 0 0 0
								4130 10 1 0 0>;
			};

			strategy_soc_50_to_75 { /* 56 ~ 75 */
				strategy_temp_little_cold =	<4560 15 0 0 0
								4570 10 1 0 0>;
				strategy_temp_cool =		<4560 15 0 0 0
								4570 10 1 0 0>;
				strategy_temp_little_cool =	<4560 20 0 0 0
								4560 15 0 0 0
								4570 10 1 0 0>;
				strategy_temp_little_cool_high = <4560 20 0 0 0
								4560 15 0 0 0
								4570 10 1 0 0>;
				strategy_temp_normal_low =	<4560 25 0 0 0
								4560 20 0 0 0
								4560 15 0 0 0
								4570 11 1 0 0>;
				strategy_temp_normal_high =	<4560 30 0 0 0
								4560 25 0 0 0
								4560 20 0 0 0
								4570 15 0 0 0
								4530 10 1 0 0>;
				strategy_temp_warm =		<4130 11 1 0 0>;
			};

			strategy_soc_75_to_85 { /* 76 ~ 85 */
				strategy_temp_little_cold =	<4570 10 1 0 0>;
				strategy_temp_cool =		<4570 10 1 0 0>;
				strategy_temp_little_cool =	<4560 15 0 0 0
								4570 10 1 0 0>;
				strategy_temp_little_cool_high = <4560 15 0 0 0
								4570 10 1 0 0>;
				strategy_temp_normal_low =	<4560 15 0 0 0
								4570 11 1 0 0>;
				strategy_temp_normal_high =	<4560 20 0 0 0
								4570 15 0 0 0
								4530 10 1 0 0>;
				strategy_temp_warm =		<4130 11 1 0 0>;
			};

			strategy_soc_85_to_90 { /* 86 ~ 95 */
				strategy_temp_little_cold =	<4570 10 1 0 0>;
				strategy_temp_cool =		<4570 10 1 0 0>;
				strategy_temp_little_cool =	<4570 10 1 0 0>;
				strategy_temp_little_cool_high = <4570 10 1 0 0>;
				strategy_temp_normal_low =	<4570 11 1 0 0>;
				strategy_temp_normal_high =	<4570 15 0 0 0
								4530 10 1 0 0>;
				strategy_temp_warm =		<4130 11 1 0 0>;
			};
		};

		vooc_charge_strategy {
			strategy_soc_0_to_50 {
				strategy_temp_little_cold =	<4150 60 0 0 0
								 4510 52 0 0 0
								 4510 50 0 0 0
								 4510 40 0 0 0
								 4560 38 0 0 0
								 4560 30 0 0 0
								 4570 20 1 0 0>;
				strategy_temp_cool =		<4510 60 0 0 0
								 4560 52 0 0 0
								 4560 50 0 0 0
								 4560 40 0 0 0
								 4560 30 0 0 0
								 4570 20 1 0 0>;
				strategy_temp_little_cool =	<4560 60 0 0 0
								 4560 50 0 0 0
								 4560 40 0 0 0
								 4560 30 0 0 0
								 4570 20 1 0 0>;
				strategy_temp_little_cool_high =	<4560 60 0 0 0
								 4560 50 0 0 0
								 4560 40 0 0 0
								 4560 30 0 0 0
								 4570 20 1 0 0>;
				strategy_temp_normal_low =	<4560 60 0 0 0
								 4560 50 0 0 0
								 4560 40 0 0 0
								 4560 30 0 0 0
								 4570 22 1 0 0>;
				strategy_temp_normal_high =	<4560 60 0 0 0
								 4560 50 0 0 0
								 4560 40 0 0 0
								 4570 30 0 0 0
								 4530 20 1 0 0>;
				strategy_temp_warm =		<4120 38 0 0 0
								 4120 30 0 0 0
								 4130 20 1 0 0>;
			};

			strategy_soc_0_to_50_mid {
				strategy_temp_little_cold =	<4150 60 0 0 0
								 4510 52 0 0 0
								 4510 50 0 0 0
								 4510 40 0 0 0
								 4560 38 0 0 0
								 4560 30 0 0 0
								 4570 20 1 0 0>;
				strategy_temp_cool =		<4510 60 0 0 0
								 4560 52 0 0 0
								 4560 50 0 0 0
								 4560 40 0 0 0
								 4560 30 0 0 0
								 4570 20 1 0 0>;
				strategy_temp_little_cool =	<4560 60 0 0 0
								 4560 50 0 0 0
								 4560 40 0 0 0
								 4560 30 0 0 0
								 4570 20 1 0 0>;
				strategy_temp_little_cool_high =	<4560 60 0 0 0
								 4560 50 0 0 0
								 4560 40 0 0 0
								 4560 30 0 0 0
								 4570 20 1 0 0>;
				strategy_temp_normal_low =	<4560 60 0 0 0
								 4560 50 0 0 0
								 4560 40 0 0 0
								 4560 30 0 0 0
								 4570 22 1 0 0>;
				strategy_temp_normal_high =	<4560 60 0 0 0
								 4560 50 0 0 0
								 4560 40 0 0 0
								 4570 30 0 0 0
								 4530 20 1 0 0>;
				strategy_temp_warm =		<4120 38 0 0 0
								 4120 30 0 0 0
								 4130 20 1 0 0>;
			};

			strategy_soc_0_to_50_high {
				strategy_temp_little_cold =	<4510 40 0 0 0
								 4560 38 0 0 0
								 4560 30 0 0 0
								 4570 20 1 0 0>;
				strategy_temp_cool =		<4560 50 0 0 0
								 4560 40 0 0 0
								 4560 30 0 0 0
								 4570 20 1 0 0>;
				strategy_temp_little_cool =	<4560 60 0 0 0
								 4560 50 0 0 0
								 4560 40 0 0 0
								 4560 30 0 0 0
								 4570 20 1 0 0>;
				strategy_temp_little_cool_high =	<4560 60 0 0 0
								 4560 50 0 0 0
								 4560 40 0 0 0
								 4560 30 0 0 0
								 4570 20 1 0 0>;
				strategy_temp_normal_low =	<4560 60 0 0 0
								 4560 50 0 0 0
								 4560 40 0 0 0
								 4560 30 0 0 0
								 4570 22 1 0 0>;
				strategy_temp_normal_high =	<4560 60 0 0 0
								 4560 50 0 0 0
								 4560 40 0 0 0
								 4570 30 0 0 0
								 4530 20 1 0 0>;
				strategy_temp_warm =		<4120 38 0 0 0
								 4120 30 0 0 0
								 4130 20 1 0 0>;
			};

			strategy_soc_50_to_75 {
				strategy_temp_little_cold =	<4560 30 0 0 0
								 4570 20 1 0 0>;
				strategy_temp_cool =		<4560 30 0 0 0
								 4570 20 1 0 0>;
				strategy_temp_little_cool =	<4560 40 0 0 0
								 4560 30 0 0 0
								 4570 20 1 0 0>;
				strategy_temp_little_cool_high =	<4560 40 0 0 0
								 4560 30 0 0 0
								 4570 20 1 0 0>;
				strategy_temp_normal_low =	<4560 50 0 0 0
								 4560 40 0 0 0
								 4560 30 0 0 0
								 4570 22 1 0 0>;
				strategy_temp_normal_high =	<4560 60 0 0 0
								 4560 50 0 0 0
								 4560 40 0 0 0
								 4570 30 0 0 0
								 4530 20 1 0 0>;
				strategy_temp_warm =		<4130 22 1 0 0>;
			};

			strategy_soc_75_to_85 {
				strategy_temp_little_cold =	<4570 20 1 0 0>;
				strategy_temp_cool =		<4570 20 1 0 0>;
				strategy_temp_little_cool =	<4560 30 1 0 0
								 4570 20 0 0 0>;
				strategy_temp_little_cool_high =	<4560 30 0 0 0
								 4570 20 1 0 0>;
				strategy_temp_normal_low =	<4560 30 0 0 0
								 4570 22 1 0 0>;
				strategy_temp_normal_high =	<4560 40 0 0 0
								 4570 30 0 0 0
								 4530 20 1 0 0>;
				strategy_temp_warm =		<4130 22 1 0 0>;
			};

			strategy_soc_85_to_90 {
				strategy_temp_little_cold =	<4570 20 1 0 0>;
				strategy_temp_cool =		<4570 20 1 0 0>;
				strategy_temp_little_cool =	<4570 20 1 0 0>;
				strategy_temp_little_cool_high =	<4570 20 1 0 0>;
				strategy_temp_normal_low =	<4570 22 1 0 0>;
				strategy_temp_normal_high =	<4570 30 0 0 0
								4530 20 1 0 0>;
				strategy_temp_warm =		<4130 22 1 0 0>;
			};
		};
		oplus_sc8547_cp: oplus,sc8547_cp {
			oplus,ic_type = <OPLUS_CHG_IC_CP>;
			oplus,ic_index = <0>;
			oplus,ic_func_group = <&sc8547_cp_groups>;
		};
	};
};

/* Slave CP */
&i2c13 {
	status = "okay";
	clock-frequency = <400000>;
	oplus_sc8547_slave: sc8547-charger-slave@6A {
		status = "okay";
		compatible = "oplus,sc8547d";
		reg = <0x6A>;
		ocp_reg = <0xe>;
		ovp_reg = <0x36>;/* vbat ovp 4.85v */
		vbus_ovp_reg = /bits/ 8 <0x5A>;  /* vbus ovp: 10.5v */
		oplus,use_slave_cp;

		oplus_spec,irq_gpio = <&pio 200 0x00>;
		interrupt-parent = <&pio>;
		interrupts = <200 0>;

		pinctrl-names = "charging_inter_active", "charging_inter_sleep";
		pinctrl-0 = <&slave_charging_inter_active>;
		pinctrl-1 = <&slave_charging_inter_active>;

		oplus_sc8547_slave_cp: oplus,sc8547_slave_cp {
			oplus,ic_type = <OPLUS_CHG_IC_CP>;
			oplus,ic_index = <1>;
		};
	};
};

&soc {
	oplus_chg_plc: oplus,plc_charge {
		compatible = "oplus,plc_charge";
		oplus,plc_support = <CHG_PROTOCOL_UFCS>;
		oplus,plc_soc = <90>;

		oplus,plc_strategy-data = <&buck_simple_strategy>;
		oplus,plc_strategy-names = "default";

		oplus_ufcs_step_strategy: oplus_ufcs_step_strategy {
			oplus,strategy_type = <PLC_STRATEGY_STEP>;
		};

		cp_2t1_simple_strategy: cp_2t1_simple_strategy {
			oplus,strategy_type = <PLC_STRATEGY_SIMPLE>;
			oplus,strategy_data {
				strategy_curr_ma = <1000 1500>;
			};
		};

		cp_1t1_simple_strategy: cp_1t1_simple_strategy {
			oplus,strategy_type = <PLC_STRATEGY_SIMPLE>;
			oplus,strategy_data {
				strategy_curr_ma = <2000 3000>;
			};
		};

		buck_simple_strategy: buck_simple_strategy {
			oplus,strategy_type = <PLC_STRATEGY_SIMPLE>;
		};
	};
};

&rt6160_bus5 {
	status = "disabled";
};

#include "oplus-chg-24825-pps.dtsi"
